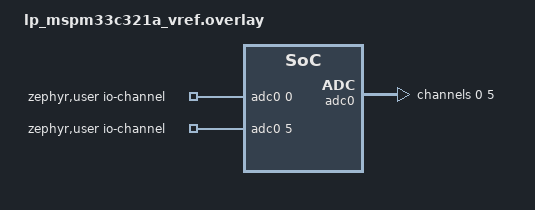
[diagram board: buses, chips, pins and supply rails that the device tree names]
/*
 * Copyright (c) 2026 Texas Instruments
 *
 * SPDX-License-Identifier: Apache-2.0
 *
 * Overlay for testing internal VREF (2.5V) path of the HSADC driver.
 */

#include <zephyr/dt-bindings/adc/adc.h>

/ {
	zephyr,user {
		io-channels = <&adc0 0>, <&adc0 5>;
	};
};

&adc0 {
	ti,clk-divider = <2>;
	vref-mv = <2500>;  /* Internal 2.5V reference */
	#address-cells = <1>;
	#size-cells = <0>;

	channel@0 {
		reg = <0>;
		zephyr,gain = "ADC_GAIN_1";
		zephyr,reference = "ADC_REF_INTERNAL";
		zephyr,acquisition-time = <ADC_ACQ_TIME(ADC_ACQ_TIME_TICKS, 200)>;
		zephyr,resolution = <12>;
	};

	channel@5 {
		reg = <5>;
		zephyr,gain = "ADC_GAIN_1";
		zephyr,reference = "ADC_REF_INTERNAL";
		zephyr,acquisition-time = <ADC_ACQ_TIME(ADC_ACQ_TIME_TICKS, 200)>;
		zephyr,resolution = <12>;
	};
};
